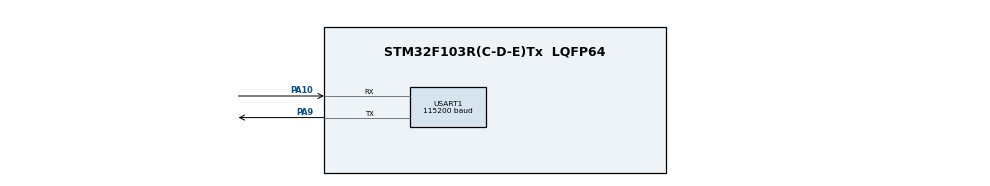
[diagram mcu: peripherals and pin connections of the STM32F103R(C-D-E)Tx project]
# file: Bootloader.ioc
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Mcu.Family=STM32F1
Mcu.Name=STM32F103R(C-D-E)Tx
Mcu.Package=LQFP64
NVIC.PriorityGroup=NVIC_PRIORITYGROUP_4
PA10.Mode=Asynchronous
PA10.Signal=USART1_RX
PA13.GPIO_Label=TMS_SWDIO
PA13.Mode=Serial_Wire
PA13.Signal=SYS_JTMS-SWDIO
PA14.GPIO_Label=TCK_SWCLK
PA14.Mode=Serial_Wire
PA14.Signal=SYS_JTCK-SWCLK
PA9.Mode=Asynchronous
PA9.Signal=USART1_TX
PD0-OSC_IN.Mode=HSE-External-Oscillator
PD0-OSC_IN.Signal=RCC_OSC_IN
PD1-OSC_OUT.Mode=HSE-External-Oscillator
PD1-OSC_OUT.Signal=RCC_OSC_OUT
ProjectManager.HeapSize=0x200
ProjectManager.StackSize=0x400
ProjectManager.TargetToolchain=STM32CubeIDE
RCC.APB1Freq_Value=8000000
RCC.APB2Freq_Value=8000000
USART1.BaudRate=115200
USART1.Mode=MODE_TX_RX
USART1.OverSampling=UART_OVERSAMPLING_16
USART1.Parity=PARITY_NONE
USART1.StopBits=STOPBITS_1
USART1.VirtualMode=VM_ASYNC
USART1.WordLength=WORDLENGTH_8B
board=STM32VLDISCOVERY

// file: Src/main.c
/* USER CODE BEGIN Header */
/**
 ******************************************************************************
 * @file           : main.c
 * @brief          : Main program body
 ******************************************************************************
 * @attention
 *
 * Copyright (c) 2022 STMicroelectronics.
 * All rights reserved.
 *
 * This software is licensed under terms that can be found in the LICENSE file
 * in the root directory of this software component.
 * If no LICENSE file comes with this software, it is provided AS-IS.
 *
 ******************************************************************************
 */
/* USER CODE END Header */
#include "main.h"

/* USER CODE BEGIN Includes */
#include "xmodem.h"
#include "flash.h"
/* USER CODE END Includes */

UART_HandleTypeDef huart1;

/* USER CODE BEGIN PV */
/* Private variables ---------------------------------------------------------*/

/* USER CODE END PV */

void SystemClock_Config(void);
static void MX_GPIO_Init(void);
static void MX_USART1_UART_Init(void);
/* USER CODE BEGIN PFP */
/* Private function prototypes -----------------------------------------------*/

/* USER CODE END PFP */

int main(void)
{
	/* USER CODE BEGIN 1 */
	uint8_t uart_response = 0;
	uart_status uart_stat;
	uint32_t programming_address = -1;
	/* USER CODE END 1 */

	/* MCU Configuration--------------------------------------------------------*/

	/* Reset of all peripherals, Initializes the Flash interface and the Systick. */
	HAL_Init();

	/* Configure the system clock */
	SystemClock_Config();

	/* Initialize all configured peripherals */
	MX_GPIO_Init();
	MX_USART1_UART_Init();
	/* USER CODE BEGIN 2 */
	/* Send welcome message on startup. */
	uart_transmit_str((uint8_t*)"\n\rUART Bootloader\n\r");
	uart_transmit_str((uint8_t*)"MODE: ");

	/* 'A' - switch to application programming mode, 'B' - bootloader programming mode. Otherwise load internal SW. */
	uart_stat = uart_receive(&uart_response, 1);
	if(uart_stat == UART_OK)
	{
		switch(uart_response)
		{
			case 'A':
				uart_transmit_str((uint8_t*)"Application programming\n\r");
				programming_address = FLASH_APP_START_ADDRESS;
				break;
			case 'B':
				uart_transmit_str((uint8_t*)"Bootloader programming\n\r");
				programming_address = FLASH_BASE;
				break;
			default:
				uart_transmit_str((uint8_t*)"Unknown\n\r");
				break;
		}
		if(programming_address != -1)
		{
			while (1)
			{
				/* Ask for new data and start the Xmodem protocol. */
				uart_transmit_str((uint8_t*)"ready\n\r");
				xmodem_receive(programming_address);
				/* We only exit the xmodem protocol, if there are any errors.
				 * In that case, notify the user and start over. */
				uart_transmit_str((uint8_t*)"failed\n\r");
			}
		}
	}else
	{
		uart_transmit_str((uint8_t*)"Internal boot\n\r");
		flash_jump_to_app();
	}
	/* USER CODE END 2 */
}

void SystemClock_Config(void)
{
	RCC_OscInitTypeDef RCC_OscInitStruct = {0};
	RCC_ClkInitTypeDef RCC_ClkInitStruct = {0};

	/** Initializes the RCC Oscillators according to the specified parameters
	 * in the RCC_OscInitTypeDef structure.
	 */
	RCC_OscInitStruct.OscillatorType = RCC_OSCILLATORTYPE_HSI;
	RCC_OscInitStruct.HSIState = RCC_HSI_ON;
	RCC_OscInitStruct.HSICalibrationValue = RCC_HSICALIBRATION_DEFAULT;
	RCC_OscInitStruct.PLL.PLLState = RCC_PLL_NONE;
	if (HAL_RCC_OscConfig(&RCC_OscInitStruct) != HAL_OK)
	{
		Error_Handler();
	}
	/** Initializes the CPU, AHB and APB buses clocks
	 */
	RCC_ClkInitStruct.ClockType = RCC_CLOCKTYPE_HCLK|RCC_CLOCKTYPE_SYSCLK
			|RCC_CLOCKTYPE_PCLK1|RCC_CLOCKTYPE_PCLK2;
	RCC_ClkInitStruct.SYSCLKSource = RCC_SYSCLKSOURCE_HSI;
	RCC_ClkInitStruct.AHBCLKDivider = RCC_SYSCLK_DIV1;
	RCC_ClkInitStruct.APB1CLKDivider = RCC_HCLK_DIV1;
	RCC_ClkInitStruct.APB2CLKDivider = RCC_HCLK_DIV1;

	if (HAL_RCC_ClockConfig(&RCC_ClkInitStruct, FLASH_LATENCY_0) != HAL_OK)
	{
		Error_Handler();
	}
}

static void MX_USART1_UART_Init(void)
{

	huart1.Instance = USART1;
	huart1.Init.BaudRate = 115200;
	huart1.Init.WordLength = UART_WORDLENGTH_8B;
	huart1.Init.StopBits = UART_STOPBITS_1;
	huart1.Init.Parity = UART_PARITY_NONE;
	huart1.Init.Mode = UART_MODE_TX_RX;
	huart1.Init.HwFlowCtl = UART_HWCONTROL_NONE;
	huart1.Init.OverSampling = UART_OVERSAMPLING_16;
	if (HAL_UART_Init(&huart1) != HAL_OK)
	{
		Error_Handler();
	}

}

static void MX_GPIO_Init(void)
{

	/* GPIO Ports Clock Enable */
	__HAL_RCC_GPIOD_CLK_ENABLE();
	__HAL_RCC_GPIOA_CLK_ENABLE();

}

void Error_Handler(void)
{
	while(1)
	{
	}
}
